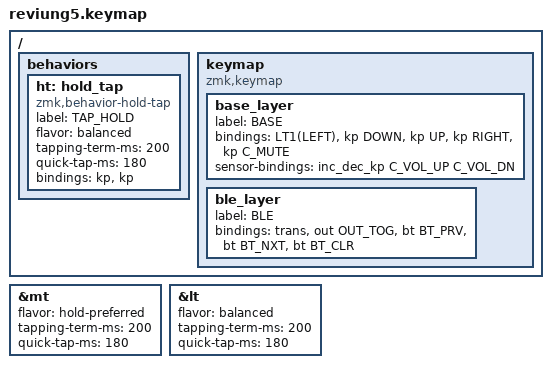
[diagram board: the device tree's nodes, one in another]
/*
 * Copyright (c) 2022 The ZMK Contributors
 *
 * SPDX-License-Identifier: MIT
 */

#include <behaviors.dtsi>
#include <dt-bindings/zmk/keys.h>
#include <dt-bindings/zmk/bt.h>
#include <dt-bindings/zmk/outputs.h>

#define BASE 0
#define BLE 1

&mt {
    flavor = "hold-preferred";
    tapping-term-ms = <200>;
    quick-tap-ms = <180>;
};

&lt {
    flavor = "balanced";
    tapping-term-ms = <200>;
    quick-tap-ms = <180>;
};

#define LT1(k1) &lt 1 k1

/ {
    behaviors {
        ht: hold_tap {
            label = "TAP_HOLD";
            compatible = "zmk,behavior-hold-tap";
            #binding-cells = <2>;
            flavor = "balanced";
            tapping-term-ms = <200>;
            quick-tap-ms = <180>;
            bindings = <&kp>, <&kp>;
        };
    };
    keymap {
        compatible = "zmk,keymap";

        base_layer {
          label = "BASE";
          bindings = <
            // ╭──────────────┬──────────────┬──────────────┬──────────────┬──────────────╮
                 LT1(LEFT)     &kp DOWN       &kp UP         &kp RIGHT      &kp C_MUTE
            // ╰──────────────┴──────────────┴──────────────┴──────────────┴──────────────╯
          >;
          sensor-bindings = <&inc_dec_kp C_VOL_UP C_VOL_DN>;
        };

        ble_layer {
          label = "BLE";
          bindings = <
            // ╭──────────────┬──────────────┬──────────────┬──────────────┬──────────────╮
                 &trans        &out OUT_TOG   &bt BT_PRV     &bt BT_NXT     &bt BT_CLR
            // ╰──────────────┴──────────────┴──────────────┴──────────────┴──────────────╯
          >;
        };
    };
};
